# CH32F20xxx register map
Vendor: WCH Ltd.; File version: 1.1
Registers are 32-bit, read-write, reset 0x0 unless marked. A register's access mark holds for its fields unless they carry their own. Offsets are from the block's base; [hi:lo] are bit positions; {n}, {i} and the like mark numbered series.

## TRNG — Random number generator
Base 0x40023C00
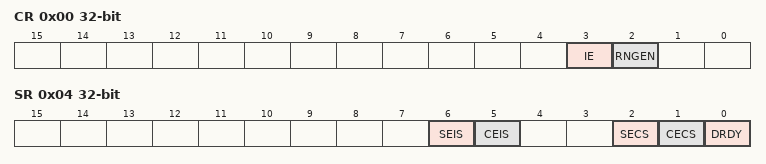
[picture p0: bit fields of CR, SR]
0x00 CR — control register
  [3] IE — Interrupt enable
  [2] RNGEN — Random number generator enable
0x04 SR access per field — status register
  [6] SEIS rw — Seed error interrupt status
  [5] CEIS rw — Clock error interrupt status
  [2] SECS ro — Seed error current status
  [1] CECS ro — Clock error current status
  [0] DRDY ro — Data ready
0x08 DR ro — data register
  [31:0] RNDATA — Random data

## USB — Universal serial bus full-speed device interface
Base 0x40005C00
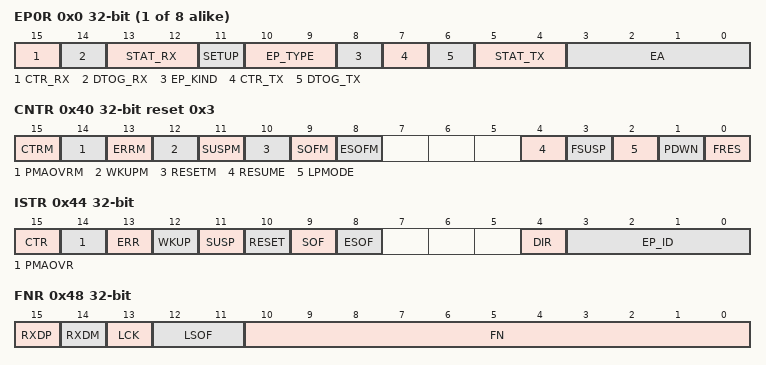
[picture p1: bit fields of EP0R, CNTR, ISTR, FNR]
{0x0+4i} EP{i}R (i=0..7) — endpoint {i} register
  [15] CTR_RX — Correct transfer for reception
  [14] DTOG_RX — Data Toggle, for reception transfers
  [13:12] STAT_RX — Status bits, for reception transfers
  [11] SETUP — Setup transaction completed
  [10:9] EP_TYPE — Endpoint type
  [8] EP_KIND — Endpoint kind
  [7] CTR_TX — Correct Transfer for transmission
  [6] DTOG_TX — Data Toggle, for transmission transfers
  [5:4] STAT_TX — Status bits, for transmission transfers
  [3:0] EA — Endpoint address
0x40 CNTR reset 0x3 — control register
  [15] CTRM — Correct transfer interrupt mask
  [14] PMAOVRM — Packet memory area over / underrun interrupt mask
  [13] ERRM — Error interrupt mask
  [12] WKUPM — Wakeup interrupt mask
  [11] SUSPM — Suspend mode interrupt mask
  [10] RESETM — USB reset interrupt mask
  [9] SOFM — Start of frame interrupt mask
  [8] ESOFM — Expected start of frame interrupt mask
  [4] RESUME — Resume request
  [3] FSUSP — Force suspend
  [2] LPMODE — Low-power mode
  [1] PDWN — Power down
  [0] FRES — Force USB Reset
0x44 ISTR — interrupt status register
  [15] CTR — Correct transfer
  [14] PMAOVR — Packet memory area over / underrun
  [13] ERR — Error
  [12] WKUP — Wakeup
  [11] SUSP — Suspend mode request
  [10] RESET — reset request
  [9] SOF — start of frame
  [8] ESOF — Expected start frame
  [4] DIR — Direction of transaction
  [3:0] EP_ID — Endpoint Identifier
0x48 FNR ro — frame number register
  [15] RXDP — Receive data + line status
  [14] RXDM — Receive data - line status
  [13] LCK — Locked
  [12:11] LSOF — Lost SOF
  [10:0] FN — Frame number
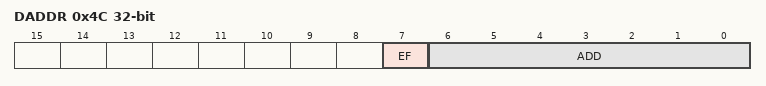
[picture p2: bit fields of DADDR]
0x4C DADDR — device address
  [7] EF — Enable function
  [6:0] ADD — Device address
0x50 BTABLE — Buffer table address
  [15:3] BTABLE — Buffer table

## CAN1 — Controller area network
Base 0x40006400
Same registers: CAN2 0x40006400
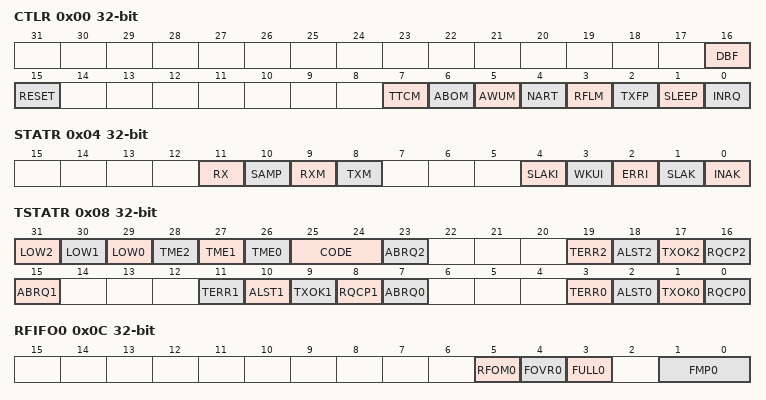
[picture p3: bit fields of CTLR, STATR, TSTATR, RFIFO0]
0x00 CTLR
  [16] DBF, [15] RESET, [7] TTCM, [6] ABOM, [5] AWUM, [4] NART, [3] RFLM, [2] TXFP, [1] SLEEP, [0] INRQ
0x04 STATR access per field
  [11] RX ro, [10] SAMP ro, [9] RXM ro, [8] TXM ro, [4] SLAKI rw, [3] WKUI rw, [2] ERRI rw, [1] SLAK ro, [0] INAK ro
0x08 TSTATR access per field
  [31] LOW2 ro — Lowest priority flag for mailbox 2
  [30] LOW1 ro — Lowest priority flag for mailbox 1
  [29] LOW0 ro — Lowest priority flag for mailbox 0
  [28] TME2 ro — Lowest priority flag for mailbox 2
  [27] TME1 ro — Lowest priority flag for mailbox 1
  [26] TME0 ro — Lowest priority flag for mailbox 0
  [25:24] CODE ro
  [23] ABRQ2 rw
  [19] TERR2 rw
  [18] ALST2 rw
  [17] TXOK2 rw
  [16] RQCP2 rw
  [15] ABRQ1 rw
  [11] TERR1 rw
  [10] ALST1 rw
  [9] TXOK1 rw
  [8] RQCP1 rw
  [7] ABRQ0 rw
  [3] TERR0 rw
  [2] ALST0 rw
  [1] TXOK0 rw
  [0] RQCP0 rw
0x0C RFIFO0 access per field
  [5] RFOM0 rw, [4] FOVR0 rw, [3] FULL0 rw, [1:0] FMP0 ro
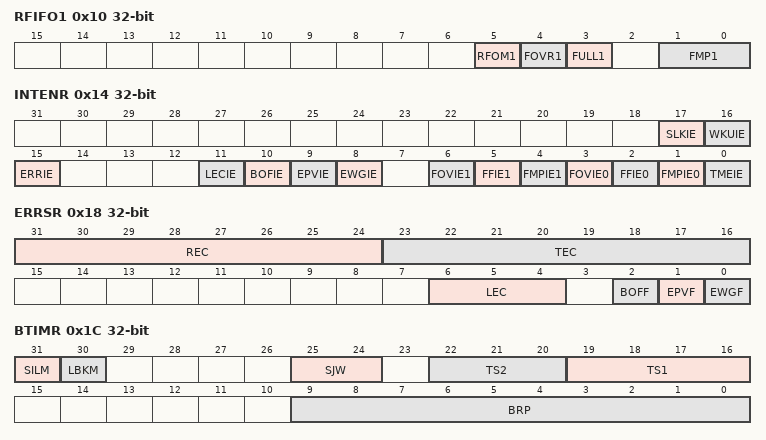
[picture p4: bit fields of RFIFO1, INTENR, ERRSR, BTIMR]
0x10 RFIFO1 access per field
  [5] RFOM1 rw, [4] FOVR1 rw, [3] FULL1 rw, [1:0] FMP1 ro
0x14 INTENR
  [17] SLKIE, [16] WKUIE, [15] ERRIE, [11] LECIE, [10] BOFIE, [9] EPVIE, [8] EWGIE, [6] FOVIE1, [5] FFIE1, [4] FMPIE1, [3] FOVIE0, [2] FFIE0, [1] FMPIE0, [0] TMEIE
0x18 ERRSR access per field
  [31:24] REC ro, [23:16] TEC ro, [6:4] LEC rw, [2] BOFF ro, [1] EPVF ro, [0] EWGF ro
0x1C BTIMR
  [31] SILM, [30] LBKM, [25:24] SJW, [22:20] TS2, [19:16] TS1, [9:0] BRP
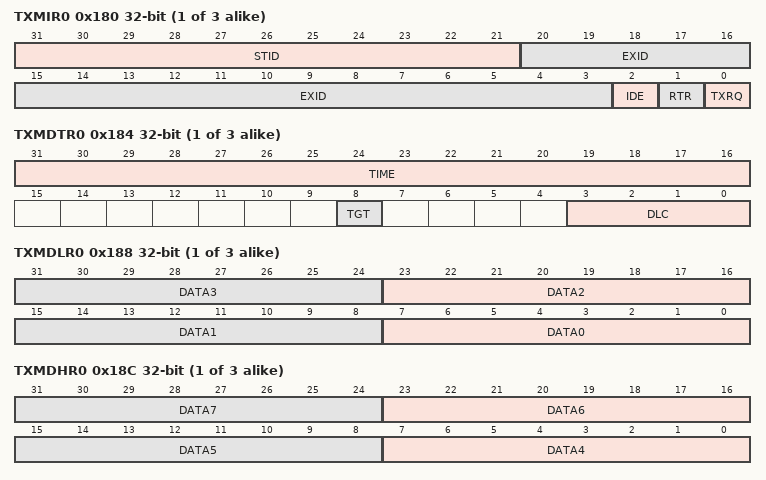
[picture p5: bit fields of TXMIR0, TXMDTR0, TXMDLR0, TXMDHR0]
{0x180+0x10*i} TXMIR{i} (i=0..2)
  [31:21] STID, [20:3] EXID, [2] IDE, [1] RTR, [0] TXRQ
{0x184+0x10*i} TXMDTR{i} (i=0..2)
  [31:16] TIME, [8] TGT, [3:0] DLC
{0x188+0x10*i} TXMDLR{i} (i=0..2)
  [8n+7:8n] DATA{n} (n=0..3)
{0x18C+0x10*i} TXMDHR{i} (i=0..2)
  [8n-25:8n-32] DATA{n} (n=4..7)
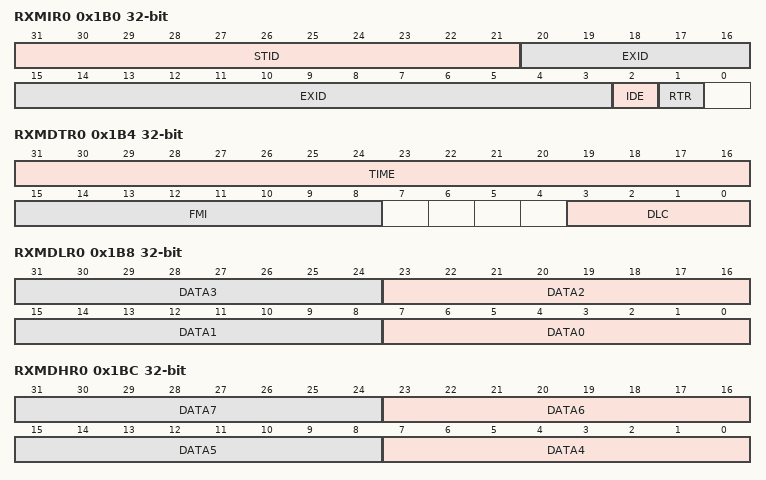
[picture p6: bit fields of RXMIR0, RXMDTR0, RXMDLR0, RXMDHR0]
0x1B0 RXMIR0 ro
  [31:21] STID, [20:3] EXID, [2] IDE, [1] RTR
0x1B4 RXMDTR0 ro
  [31:16] TIME, [15:8] FMI, [3:0] DLC
0x1B8 RXMDLR0 ro
  [8n+7:8n] DATA{n} (n=0..3)
0x1BC RXMDHR0 ro
  [8n-25:8n-32] DATA{n} (n=4..7)
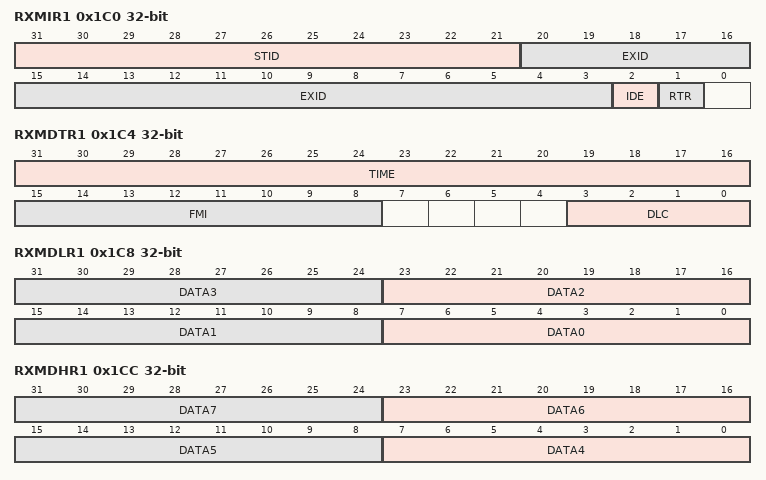
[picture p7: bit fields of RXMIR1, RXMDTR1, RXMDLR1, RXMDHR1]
0x1C0 RXMIR1 ro
  [31:21] STID, [20:3] EXID, [2] IDE, [1] RTR
0x1C4 RXMDTR1 ro
  [31:16] TIME, [15:8] FMI, [3:0] DLC
0x1C8 RXMDLR1 ro
  [8n+7:8n] DATA{n} (n=0..3)
0x1CC RXMDHR1 ro
  [8n-25:8n-32] DATA{n} (n=4..7)
0x200 FCTLR
  [0] FINIT
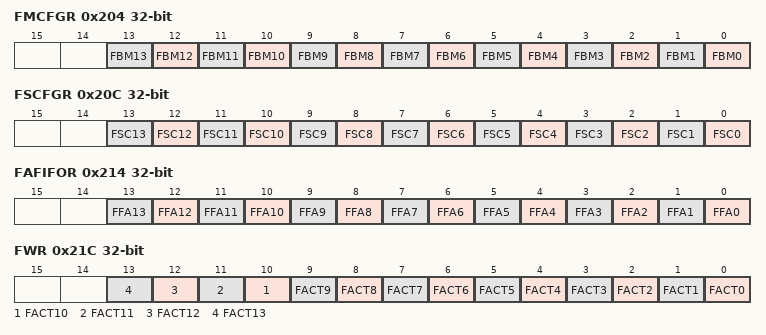
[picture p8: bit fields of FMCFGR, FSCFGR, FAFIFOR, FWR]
0x204 FMCFGR
  [n] FBM{n} (n=0..13) — Filter mode
0x20C FSCFGR
  [n] FSC{n} (n=0..13) — Filter scale configuration
0x214 FAFIFOR
  [n] FFA{n} (n=0..13) — Filter FIFO assignment for filter {n}
0x21C FWR
  [n] FACT{n} (n=0..13) — Filter active
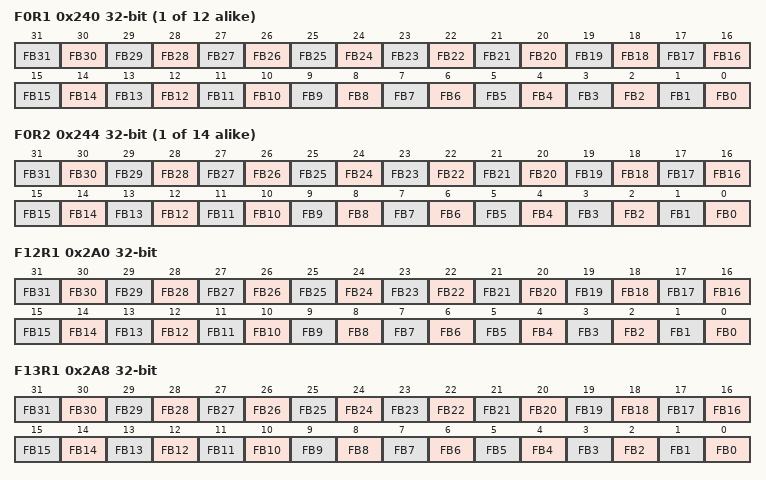
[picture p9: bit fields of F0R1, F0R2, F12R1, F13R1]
{0x240+8i} F{i}R1 (i=0..11) — Filter bank {i} register 1
  [n] FB{n} (n=0..31) — Filter bits
{0x244+8i} F{i}R2 (i=0..13) — Filter bank {i} register 2
  [n] FB{n} (n=0..31) — Filter bits
0x2A0 F12R1 — Filter bank 4 register 1
  [n] FB{n} (n=0..31) — Filter bits
0x2A8 F13R1 — Filter bank 13 register 1
  [n] FB{n} (n=0..31) — Filter bits
